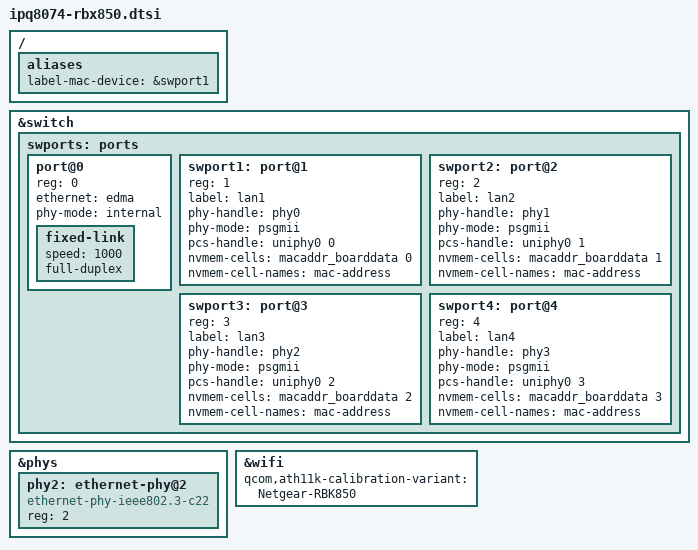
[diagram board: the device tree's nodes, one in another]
// SPDX-License-Identifier: GPL-2.0-or-later OR MIT
/*
 * Copyright (c) 2026 Michael Lotz <mmlr@mlotz.ch>
 */

/dts-v1/;

#include "ipq8074-rbx750_850.dtsi"

/ {
	aliases {
		label-mac-device = &swport1;
	};
};

&switch {
	swports: ports {
		#address-cells = <1>;
		#size-cells = <0>;

		port@0 {
			reg = <0>;
			ethernet = <&edma>;
			phy-mode = "internal";

			fixed-link {
				speed = <1000>;
				full-duplex;
			};
		};

		swport1: port@1 {
			reg = <1>;
			label = "lan1";
			phy-handle = <&phy0>;
			phy-mode = "psgmii";
			pcs-handle = <&uniphy0 0>;
			nvmem-cells = <&macaddr_boarddata 0>;
			nvmem-cell-names = "mac-address";
		};

		swport2: port@2 {
			reg = <2>;
			label = "lan2";
			phy-handle = <&phy1>;
			phy-mode = "psgmii";
			pcs-handle = <&uniphy0 1>;
			nvmem-cells = <&macaddr_boarddata 1>;
			nvmem-cell-names = "mac-address";
		};

		swport3: port@3 {
			reg = <3>;
			label = "lan3";
			phy-handle = <&phy2>;
			phy-mode = "psgmii";
			pcs-handle = <&uniphy0 2>;
			nvmem-cells = <&macaddr_boarddata 2>;
			nvmem-cell-names = "mac-address";
		};

		swport4: port@4 {
			reg = <4>;
			label = "lan4";
			phy-handle = <&phy3>;
			phy-mode = "psgmii";
			pcs-handle = <&uniphy0 3>;
			nvmem-cells = <&macaddr_boarddata 3>;
			nvmem-cell-names = "mac-address";
		};
	};
};

&phys {
	phy2: ethernet-phy@2 {
		compatible = "ethernet-phy-ieee802.3-c22";
		reg = <2>;
	};
};

&wifi {
	qcom,ath11k-calibration-variant = "Netgear-RBK850";
};
